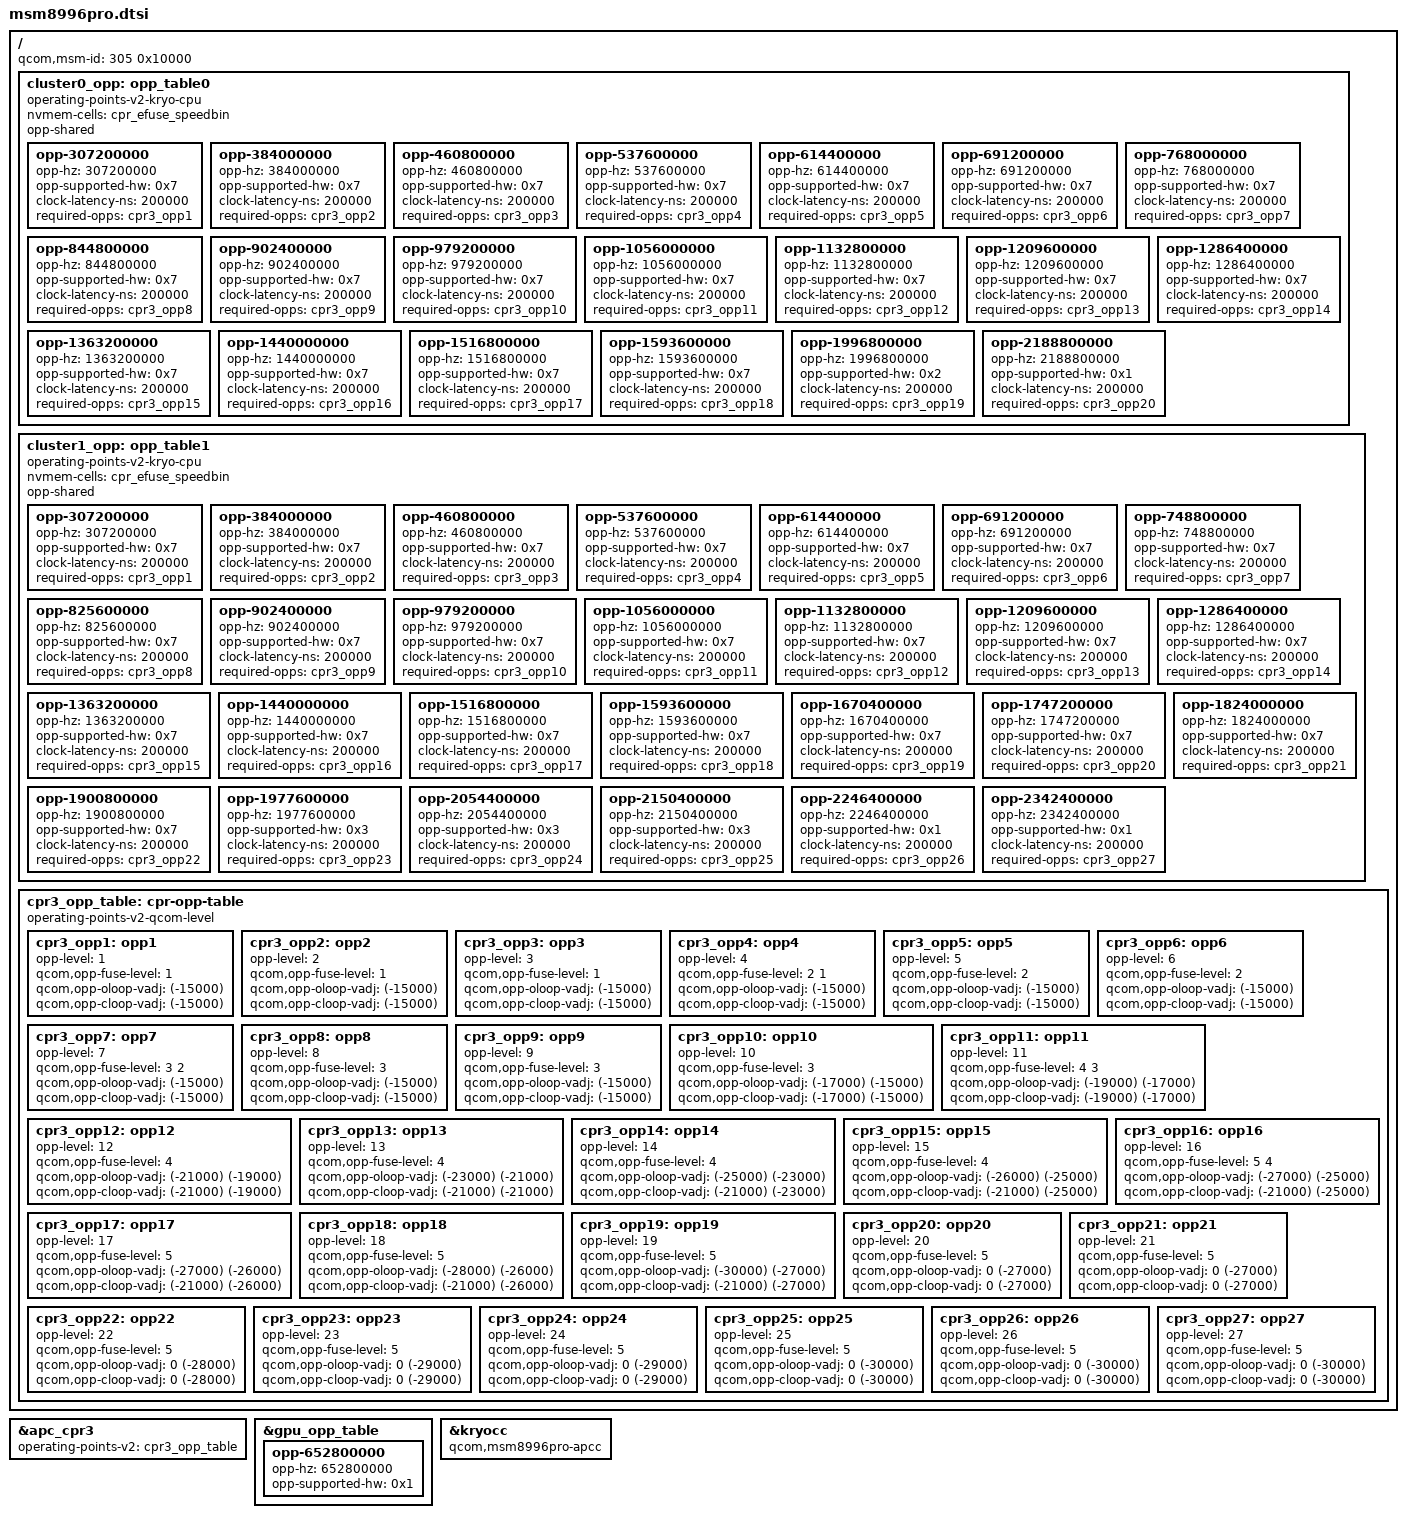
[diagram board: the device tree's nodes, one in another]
// SPDX-License-Identifier: BSD-3-Clause
/*
 * Copyright (c) 2021, Yassine Oudjana <y.oudjana@protonmail.com>
 */

#include "msm8996.dtsi"

/*
 * MSM8996 Pro (also known as MSM8996SG) is a revision of MSM8996 with
 * different CPU, CBF and GPU frequencies as well as CPR parameters.
 */
/delete-node/ &cluster0_opp;
/delete-node/ &cluster1_opp;

/ {
	qcom,msm-id = <305 0x10000>;

	cluster0_opp: opp_table0 {
		compatible = "operating-points-v2-kryo-cpu";
		nvmem-cells = <&cpr_efuse_speedbin>;
		opp-shared;

		opp-307200000 {
			opp-hz = /bits/ 64 <307200000>;
			opp-supported-hw = <0x7>;
			clock-latency-ns = <200000>;
			required-opps = <&cpr3_opp1>;
		};
		opp-384000000 {
			opp-hz = /bits/ 64 <384000000>;
			opp-supported-hw = <0x7>;
			clock-latency-ns = <200000>;
			required-opps = <&cpr3_opp2>;
		};
		opp-460800000 {
			opp-hz = /bits/ 64 <460800000>;
			opp-supported-hw = <0x7>;
			clock-latency-ns = <200000>;
			required-opps = <&cpr3_opp3>;
		};
		opp-537600000 {
			opp-hz = /bits/ 64 <537600000>;
			opp-supported-hw = <0x7>;
			clock-latency-ns = <200000>;
			required-opps = <&cpr3_opp4>;
		};
		opp-614400000 {
			opp-hz = /bits/ 64 <614400000>;
			opp-supported-hw = <0x7>;
			clock-latency-ns = <200000>;
			required-opps = <&cpr3_opp5>;
		};
		opp-691200000 {
			opp-hz = /bits/ 64 <691200000>;
			opp-supported-hw = <0x7>;
			clock-latency-ns = <200000>;
			required-opps = <&cpr3_opp6>;
		};
		opp-768000000 {
			opp-hz = /bits/ 64 <768000000>;
			opp-supported-hw = <0x7>;
			clock-latency-ns = <200000>;
			required-opps = <&cpr3_opp7>;
		};
		opp-844800000 {
			opp-hz = /bits/ 64 <844800000>;
			opp-supported-hw = <0x7>;
			clock-latency-ns = <200000>;
			required-opps = <&cpr3_opp8>;
		};
		opp-902400000 {
			opp-hz = /bits/ 64 <902400000>;
			opp-supported-hw = <0x7>;
			clock-latency-ns = <200000>;
			required-opps = <&cpr3_opp9>;
		};
		opp-979200000 {
			opp-hz = /bits/ 64 <979200000>;
			opp-supported-hw = <0x7>;
			clock-latency-ns = <200000>;
			required-opps = <&cpr3_opp10>;
		};
		opp-1056000000 {
			opp-hz = /bits/ 64 <1056000000>;
			opp-supported-hw = <0x7>;
			clock-latency-ns = <200000>;
			required-opps = <&cpr3_opp11>;
		};
		opp-1132800000 {
			opp-hz = /bits/ 64 <1132800000>;
			opp-supported-hw = <0x7>;
			clock-latency-ns = <200000>;
			required-opps = <&cpr3_opp12>;
		};
		opp-1209600000 {
			opp-hz = /bits/ 64 <1209600000>;
			opp-supported-hw = <0x7>;
			clock-latency-ns = <200000>;
			required-opps = <&cpr3_opp13>;
		};
		opp-1286400000 {
			opp-hz = /bits/ 64 <1286400000>;
			opp-supported-hw = <0x7>;
			clock-latency-ns = <200000>;
			required-opps = <&cpr3_opp14>;
		};
		opp-1363200000 {
			opp-hz = /bits/ 64 <1363200000>;
			opp-supported-hw = <0x7>;
			clock-latency-ns = <200000>;
			required-opps = <&cpr3_opp15>;
		};
		opp-1440000000 {
			opp-hz = /bits/ 64 <1440000000>;
			opp-supported-hw = <0x7>;
			clock-latency-ns = <200000>;
			required-opps = <&cpr3_opp16>;
		};
		opp-1516800000 {
			opp-hz = /bits/ 64 <1516800000>;
			opp-supported-hw = <0x7>;
			clock-latency-ns = <200000>;
			required-opps = <&cpr3_opp17>;
		};
		opp-1593600000 {
			opp-hz = /bits/ 64 <1593600000>;
			opp-supported-hw = <0x7>;
			clock-latency-ns = <200000>;
			required-opps = <&cpr3_opp18>;
		};
		opp-1996800000 {
			opp-hz = /bits/ 64 <1996800000>;
			opp-supported-hw = <0x2>;
			clock-latency-ns = <200000>;
			required-opps = <&cpr3_opp19>;
		};
		opp-2188800000 {
			opp-hz = /bits/ 64 <2188800000>;
			opp-supported-hw = <0x1>;
			clock-latency-ns = <200000>;
			required-opps = <&cpr3_opp20>;
		};
	};

	cluster1_opp: opp_table1 {
		compatible = "operating-points-v2-kryo-cpu";
		nvmem-cells = <&cpr_efuse_speedbin>;
		opp-shared;

		opp-307200000 {
			opp-hz = /bits/ 64 <307200000>;
			opp-supported-hw = <0x7>;
			clock-latency-ns = <200000>;
			required-opps = <&cpr3_opp1>;
		};
		opp-384000000 {
			opp-hz = /bits/ 64 <384000000>;
			opp-supported-hw = <0x7>;
			clock-latency-ns = <200000>;
			required-opps = <&cpr3_opp2>;
		};
		opp-460800000 {
			opp-hz = /bits/ 64 <460800000>;
			opp-supported-hw = <0x7>;
			clock-latency-ns = <200000>;
			required-opps = <&cpr3_opp3>;
		};
		opp-537600000 {
			opp-hz = /bits/ 64 <537600000>;
			opp-supported-hw = <0x7>;
			clock-latency-ns = <200000>;
			required-opps = <&cpr3_opp4>;
		};
		opp-614400000 {
			opp-hz = /bits/ 64 <614400000>;
			opp-supported-hw = <0x7>;
			clock-latency-ns = <200000>;
			required-opps = <&cpr3_opp5>;
		};
		opp-691200000 {
			opp-hz = /bits/ 64 <691200000>;
			opp-supported-hw = <0x7>;
			clock-latency-ns = <200000>;
			required-opps = <&cpr3_opp6>;
		};
		opp-748800000 {
			opp-hz = /bits/ 64 <748800000>;
			opp-supported-hw = <0x7>;
			clock-latency-ns = <200000>;
			required-opps = <&cpr3_opp7>;
		};
		opp-825600000 {
			opp-hz = /bits/ 64 <825600000>;
			opp-supported-hw = <0x7>;
			clock-latency-ns = <200000>;
			required-opps = <&cpr3_opp8>;
		};
		opp-902400000 {
			opp-hz = /bits/ 64 <902400000>;
			opp-supported-hw = <0x7>;
			clock-latency-ns = <200000>;
			required-opps = <&cpr3_opp9>;
		};
		opp-979200000 {
			opp-hz = /bits/ 64 <979200000>;
			opp-supported-hw = <0x7>;
			clock-latency-ns = <200000>;
			required-opps = <&cpr3_opp10>;
		};
		opp-1056000000 {
			opp-hz = /bits/ 64 <1056000000>;
			opp-supported-hw = <0x7>;
			clock-latency-ns = <200000>;
			required-opps = <&cpr3_opp11>;
		};
		opp-1132800000 {
			opp-hz = /bits/ 64 <1132800000>;
			opp-supported-hw = <0x7>;
			clock-latency-ns = <200000>;
			required-opps = <&cpr3_opp12>;
		};
		opp-1209600000 {
			opp-hz = /bits/ 64 <1209600000>;
			opp-supported-hw = <0x7>;
			clock-latency-ns = <200000>;
			required-opps = <&cpr3_opp13>;
		};
		opp-1286400000 {
			opp-hz = /bits/ 64 <1286400000>;
			opp-supported-hw = <0x7>;
			clock-latency-ns = <200000>;
			required-opps = <&cpr3_opp14>;
		};
		opp-1363200000 {
			opp-hz = /bits/ 64 <1363200000>;
			opp-supported-hw = <0x7>;
			clock-latency-ns = <200000>;
			required-opps = <&cpr3_opp15>;
		};
		opp-1440000000 {
			opp-hz = /bits/ 64 <1440000000>;
			opp-supported-hw = <0x7>;
			clock-latency-ns = <200000>;
			required-opps = <&cpr3_opp16>;
		};
		opp-1516800000 {
			opp-hz = /bits/ 64 <1516800000>;
			opp-supported-hw = <0x7>;
			clock-latency-ns = <200000>;
			required-opps = <&cpr3_opp17>;
		};
		opp-1593600000 {
			opp-hz = /bits/ 64 <1593600000>;
			opp-supported-hw = <0x7>;
			clock-latency-ns = <200000>;
			required-opps = <&cpr3_opp18>;
		};
		opp-1670400000 {
			opp-hz = /bits/ 64 <1670400000>;
			opp-supported-hw = <0x7>;
			clock-latency-ns = <200000>;
			required-opps = <&cpr3_opp19>;
		};
		opp-1747200000 {
			opp-hz = /bits/ 64 <1747200000>;
			opp-supported-hw = <0x7>;
			clock-latency-ns = <200000>;
			required-opps = <&cpr3_opp20>;
		};
		opp-1824000000 {
			opp-hz = /bits/ 64 <1824000000>;
			opp-supported-hw = <0x7>;
			clock-latency-ns = <200000>;
			required-opps = <&cpr3_opp21>;
		};
		opp-1900800000 {
			opp-hz = /bits/ 64 <1900800000>;
			opp-supported-hw = <0x7>;
			clock-latency-ns = <200000>;
			required-opps = <&cpr3_opp22>;
		};
		opp-1977600000 {
			opp-hz = /bits/ 64 <1977600000>;
			opp-supported-hw = <0x3>;
			clock-latency-ns = <200000>;
			required-opps = <&cpr3_opp23>;
		};
		opp-2054400000 {
			opp-hz = /bits/ 64 <2054400000>;
			opp-supported-hw = <0x3>;
			clock-latency-ns = <200000>;
			required-opps = <&cpr3_opp24>;
		};
		opp-2150400000 {
			opp-hz = /bits/ 64 <2150400000>;
			opp-supported-hw = <0x3>;
			clock-latency-ns = <200000>;
			required-opps = <&cpr3_opp25>;
		};
		opp-2246400000 {
			opp-hz = /bits/ 64 <2246400000>;
			opp-supported-hw = <0x1>;
			clock-latency-ns = <200000>;
			required-opps = <&cpr3_opp26>;
		};
		opp-2342400000 {
			opp-hz = /bits/ 64 <2342400000>;
			opp-supported-hw = <0x1>;
			clock-latency-ns = <200000>;
			required-opps = <&cpr3_opp27>;
		};
	};

	cpr3_opp_table: cpr-opp-table {
		compatible = "operating-points-v2-qcom-level";

		cpr3_opp1: opp1 {
			opp-level = <1>;
			qcom,opp-fuse-level = <1>;
			qcom,opp-oloop-vadj = <(-15000)>;
			qcom,opp-cloop-vadj = <(-15000)>;
		};
		cpr3_opp2: opp2 {
			opp-level = <2>;
			qcom,opp-fuse-level = <1>;
			qcom,opp-oloop-vadj = <(-15000)>;
			qcom,opp-cloop-vadj = <(-15000)>;
		};
		cpr3_opp3: opp3 {
			opp-level = <3>;
			qcom,opp-fuse-level = <1>;
			qcom,opp-oloop-vadj = <(-15000)>;
			qcom,opp-cloop-vadj = <(-15000)>;
		};
		cpr3_opp4: opp4 {
			opp-level = <4>;
			qcom,opp-fuse-level = <2 1>;
			qcom,opp-oloop-vadj = <(-15000)>;
			qcom,opp-cloop-vadj = <(-15000)>;
		};
		cpr3_opp5: opp5 {
			opp-level = <5>;
			qcom,opp-fuse-level = <2>;
			qcom,opp-oloop-vadj = <(-15000)>;
			qcom,opp-cloop-vadj = <(-15000)>;
		};
		cpr3_opp6: opp6 {
			opp-level = <6>;
			qcom,opp-fuse-level = <2>;
			qcom,opp-oloop-vadj = <(-15000)>;
			qcom,opp-cloop-vadj = <(-15000)>;
		};
		cpr3_opp7: opp7 {
			opp-level = <7>;
			qcom,opp-fuse-level = <3 2>;
			qcom,opp-oloop-vadj = <(-15000)>;
			qcom,opp-cloop-vadj = <(-15000)>;
		};
		cpr3_opp8: opp8 {
			opp-level = <8>;
			qcom,opp-fuse-level = <3>;
			qcom,opp-oloop-vadj = <(-15000)>;
			qcom,opp-cloop-vadj = <(-15000)>;
		};
		cpr3_opp9: opp9 {
			opp-level = <9>;
			qcom,opp-fuse-level = <3>;
			qcom,opp-oloop-vadj = <(-15000)>;
			qcom,opp-cloop-vadj = <(-15000)>;
		};
		cpr3_opp10: opp10 {
			opp-level = <10>;
			qcom,opp-fuse-level = <3>;
			qcom,opp-oloop-vadj = <(-17000) (-15000)>;
			qcom,opp-cloop-vadj = <(-17000) (-15000)>;
		};
		cpr3_opp11: opp11 {
			opp-level = <11>;
			qcom,opp-fuse-level = <4 3>;
			qcom,opp-oloop-vadj = <(-19000) (-17000)>;
			qcom,opp-cloop-vadj = <(-19000) (-17000)>;
		};
		cpr3_opp12: opp12 {
			opp-level = <12>;
			qcom,opp-fuse-level = <4>;
			qcom,opp-oloop-vadj = <(-21000) (-19000)>;
			qcom,opp-cloop-vadj = <(-21000) (-19000)>;
		};
		cpr3_opp13: opp13 {
			opp-level = <13>;
			qcom,opp-fuse-level = <4>;
			qcom,opp-oloop-vadj = <(-23000) (-21000)>;
			qcom,opp-cloop-vadj = <(-21000) (-21000)>;
		};
		cpr3_opp14: opp14 {
			opp-level = <14>;
			qcom,opp-fuse-level = <4>;
			qcom,opp-oloop-vadj = <(-25000) (-23000)>;
			qcom,opp-cloop-vadj = <(-21000) (-23000)>;
		};
		cpr3_opp15: opp15 {
			opp-level = <15>;
			qcom,opp-fuse-level = <4>;
			qcom,opp-oloop-vadj = <(-26000) (-25000)>;
			qcom,opp-cloop-vadj = <(-21000) (-25000)>;
		};
		cpr3_opp16: opp16 {
			opp-level = <16>;
			qcom,opp-fuse-level = <5 4>;
			qcom,opp-oloop-vadj = <(-27000) (-25000)>;
			qcom,opp-cloop-vadj = <(-21000) (-25000)>;
		};
		cpr3_opp17: opp17 {
			opp-level = <17>;
			qcom,opp-fuse-level = <5>;
			qcom,opp-oloop-vadj = <(-27000) (-26000)>;
			qcom,opp-cloop-vadj = <(-21000) (-26000)>;
		};
		cpr3_opp18: opp18 {
			opp-level = <18>;
			qcom,opp-fuse-level = <5>;
			qcom,opp-oloop-vadj = <(-28000) (-26000)>;
			qcom,opp-cloop-vadj = <(-21000) (-26000)>;
		};
		cpr3_opp19: opp19 {
			opp-level = <19>;
			qcom,opp-fuse-level = <5>;
			qcom,opp-oloop-vadj = <(-30000) (-27000)>;
			qcom,opp-cloop-vadj = <(-21000) (-27000)>;
		};
		cpr3_opp20: opp20 {
			opp-level = <20>;
			qcom,opp-fuse-level = <5>;
			qcom,opp-oloop-vadj = <0 (-27000)>;
			qcom,opp-cloop-vadj = <0 (-27000)>;
		};
		cpr3_opp21: opp21 {
			opp-level = <21>;
			qcom,opp-fuse-level = <5>;
			qcom,opp-oloop-vadj = <0 (-27000)>;
			qcom,opp-cloop-vadj = <0 (-27000)>;
		};
		cpr3_opp22: opp22 {
			opp-level = <22>;
			qcom,opp-fuse-level = <5>;
			qcom,opp-oloop-vadj = <0 (-28000)>;
			qcom,opp-cloop-vadj = <0 (-28000)>;
		};
		cpr3_opp23: opp23 {
			opp-level = <23>;
			qcom,opp-fuse-level = <5>;
			qcom,opp-oloop-vadj = <0 (-29000)>;
			qcom,opp-cloop-vadj = <0 (-29000)>;
		};
		cpr3_opp24: opp24 {
			opp-level = <24>;
			qcom,opp-fuse-level = <5>;
			qcom,opp-oloop-vadj = <0 (-29000)>;
			qcom,opp-cloop-vadj = <0 (-29000)>;
		};
		cpr3_opp25: opp25 {
			opp-level = <25>;
			qcom,opp-fuse-level = <5>;
			qcom,opp-oloop-vadj = <0 (-30000)>;
			qcom,opp-cloop-vadj = <0 (-30000)>;
		};
		cpr3_opp26: opp26 {
			opp-level = <26>;
			qcom,opp-fuse-level = <5>;
			qcom,opp-oloop-vadj = <0 (-30000)>;
			qcom,opp-cloop-vadj = <0 (-30000)>;
		};
		cpr3_opp27: opp27 {
			opp-level = <27>;
			qcom,opp-fuse-level = <5>;
			qcom,opp-oloop-vadj = <0 (-30000)>;
			qcom,opp-cloop-vadj = <0 (-30000)>;
		};
	};
};

&apc_cpr3 {
	status = "okay";

	operating-points-v2 = <&cpr3_opp_table>;
};

&gpu_opp_table {
	/*
	 * All MSM8996 GPU OPPs are available on MSM8996 Pro,
	 * in addition to one:
	 */
	opp-652800000 {
		opp-hz = /bits/ 64 <652800000>;
		opp-supported-hw = <0x1>;
	};
};

&kryocc {
	compatible = "qcom,msm8996pro-apcc";
};
